AUTOSAR XML (schema 4-2-2)
package /STELLANTIS/EPT/ASWCs
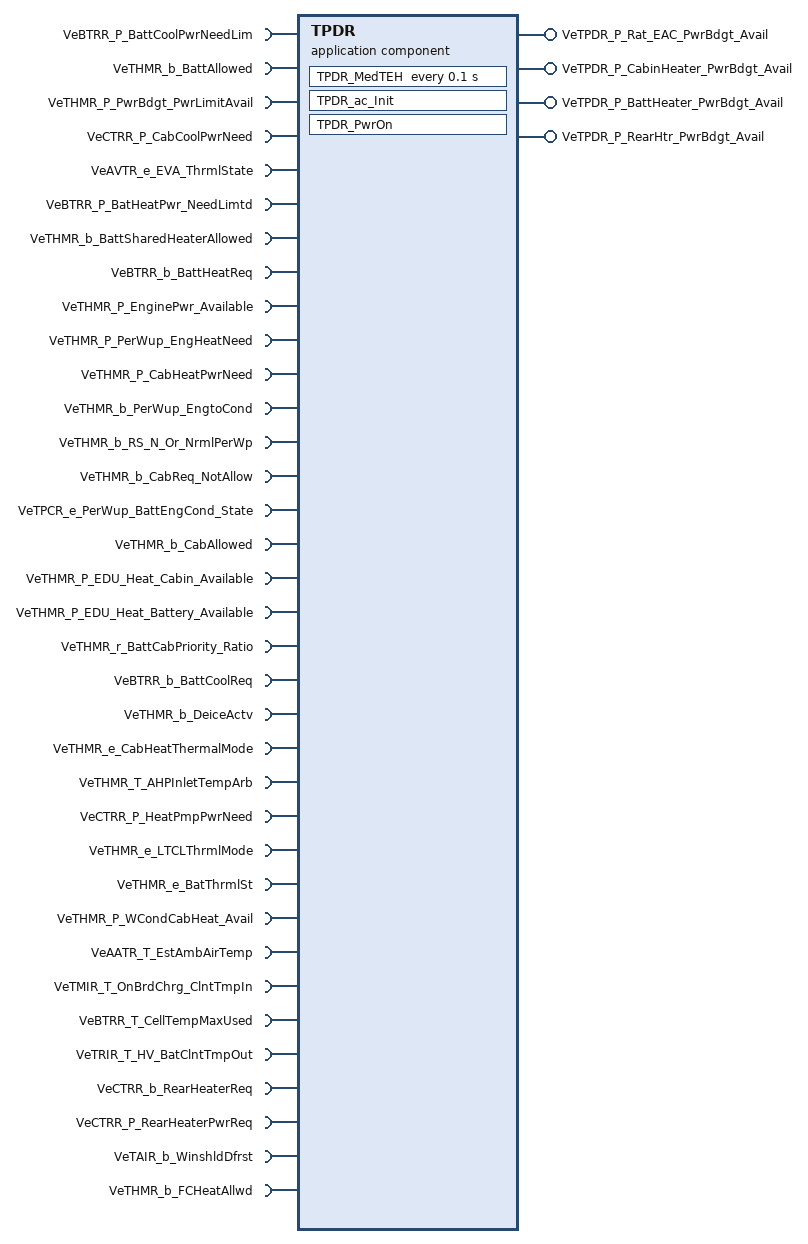
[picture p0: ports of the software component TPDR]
  application sw component type TPDR
    35 x require port:
      VeBTRR_P_BattCoolPwrNeedLim: nonqueued-receiver-com-spec{data-element=Value, init-value=0}, required-interface=VeBTRR_P_BattCoolPwrNeedLim
      VeTHMR_b_BattAllowed: nonqueued-receiver-com-spec{data-element=Value, init-value=0}, required-interface=VeTHMR_b_BattAllowed
      VeTHMR_P_PwrBdgt_PwrLimitAvail: nonqueued-receiver-com-spec{data-element=Value, init-value=0}, required-interface=VeTHMR_P_PwrBdgt_PwrLimitAvail
      VeCTRR_P_CabCoolPwrNeed: nonqueued-receiver-com-spec{data-element=Value, init-value=0}, required-interface=VeCTRR_P_CabCoolPwrNeed
      VeAVTR_e_EVA_ThrmlState: nonqueued-receiver-com-spec{data-element=Value, init-value=CeAVTR_e_NoEVACond}, required-interface=VeAVTR_e_EVA_ThrmlState
      VeBTRR_P_BatHeatPwr_NeedLimtd: nonqueued-receiver-com-spec{data-element=Value, init-value=0}, required-interface=VeBTRR_P_BatHeatPwr_NeedLimtd
      VeTHMR_b_BattSharedHeaterAllowed: nonqueued-receiver-com-spec{data-element=Value, init-value=0}, required-interface=VeTHMR_b_BattSharedHeaterAllowed
      VeBTRR_b_BattHeatReq: nonqueued-receiver-com-spec{data-element=Value, init-value=0}, required-interface=VeBTRR_b_BattHeatReq
      VeTHMR_P_EnginePwr_Available: nonqueued-receiver-com-spec{data-element=Value, init-value=0}, required-interface=VeTHMR_P_EnginePwr_Available
      VeTHMR_P_PerWup_EngHeatNeed: nonqueued-receiver-com-spec{data-element=Value, init-value=0}, required-interface=VeTHMR_P_PerWup_EngHeatNeed
      VeTHMR_P_CabHeatPwrNeed: nonqueued-receiver-com-spec{data-element=Value, init-value=0}, required-interface=VeTHMR_P_CabHeatPwrNeed
      VeTHMR_b_PerWup_EngtoCond: nonqueued-receiver-com-spec{data-element=Value, init-value=0}, required-interface=VeTHMR_b_PerWup_EngtoCond
      VeTHMR_b_RS_N_Or_NrmlPerWp: nonqueued-receiver-com-spec{data-element=Value, init-value=0}, required-interface=VeTHMR_b_RS_N_Or_NrmlPerWp
      VeTHMR_b_CabReq_NotAllow: nonqueued-receiver-com-spec{data-element=Value, init-value=0}, required-interface=VeTHMR_b_CabReq_NotAllow
      VeTPCR_e_PerWup_BattEngCond_State: nonqueued-receiver-com-spec{data-element=Value, init-value=CeTPCR_e_NoneOfEngBatt_Cond}, required-interface=VeTPCR_e_PerWup_BattEngCond_State
      VeTHMR_b_CabAllowed: nonqueued-receiver-com-spec{data-element=Value, init-value=0}, required-interface=VeTHMR_b_CabAllowed
      VeTHMR_P_EDU_Heat_Cabin_Available: nonqueued-receiver-com-spec{data-element=Value, init-value=0}, required-interface=VeTHMR_P_EDU_Heat_Cabin_Available
      VeTHMR_P_EDU_Heat_Battery_Available: nonqueued-receiver-com-spec{data-element=Value, init-value=0}, required-interface=VeTHMR_P_EDU_Heat_Battery_Available
      VeTHMR_r_BattCabPriority_Ratio: nonqueued-receiver-com-spec{data-element=Value, init-value=0}, required-interface=VeTHMR_r_BattCabPriority_Ratio
      VeBTRR_b_BattCoolReq: nonqueued-receiver-com-spec{data-element=Value, init-value=0}, required-interface=VeBTRR_b_BattCoolReq
      VeTHMR_b_DeiceActv: nonqueued-receiver-com-spec{data-element=Value, init-value=0}, required-interface=VeTHMR_b_DeiceActv
      VeTHMR_e_CabHeatThermalMode: nonqueued-receiver-com-spec{data-element=Value, init-value=CeTHMR_e_NoActvHeat}, required-interface=VeTHMR_e_CabHeatThermalMode
      VeTHMR_T_AHPInletTempArb: nonqueued-receiver-com-spec{data-element=Value, init-value=0}, required-interface=VeTHMR_T_AHPInletTempArb
      VeCTRR_P_HeatPmpPwrNeed: nonqueued-receiver-com-spec{data-element=Value, init-value=0}, required-interface=VeCTRR_P_HeatPmpPwrNeed
      VeTHMR_e_LTCLThrmlMode: nonqueued-receiver-com-spec{data-element=Value, init-value=CeTHMR_e_LTCLBalancing}, required-interface=VeTHMR_e_LTCLThrmlMode
      VeTHMR_e_BatThrmlSt: nonqueued-receiver-com-spec{data-element=Value, init-value=CeTHMR_e_NoConditioning}, required-interface=VeTHMR_e_BatThrmlSt
      VeTHMR_P_WCondCabHeat_Avail: nonqueued-receiver-com-spec{data-element=Value, init-value=0}, required-interface=VeTHMR_P_WCondCabHeat_Avail
      VeAATR_T_EstAmbAirTemp: nonqueued-receiver-com-spec{data-element=Value, init-value=0}, required-interface=VeAATR_T_EstAmbAirTemp
      VeTMIR_T_OnBrdChrg_ClntTmpIn: nonqueued-receiver-com-spec{data-element=Value, init-value=0}, required-interface=VeTMIR_T_OnBrdChrg_ClntTmpIn
      VeBTRR_T_CellTempMaxUsed: nonqueued-receiver-com-spec{data-element=Value, init-value=0}, required-interface=VeBTRR_T_CellTempMaxUsed
      VeTRIR_T_HV_BatClntTmpOut: nonqueued-receiver-com-spec{data-element=Value, init-value=0}, required-interface=VeTRIR_T_HV_BatClntTmpOut
      VeCTRR_b_RearHeaterReq: nonqueued-receiver-com-spec{data-element=Value, init-value=0}, required-interface=VeCTRR_b_RearHeaterReq
      VeCTRR_P_RearHeaterPwrReq: nonqueued-receiver-com-spec{data-element=Value, init-value=0}, required-interface=VeCTRR_P_RearHeaterPwrReq
      VeTAIR_b_WinshldDfrst: nonqueued-receiver-com-spec{data-element=Value, init-value=0}, required-interface=VeTAIR_b_WinshldDfrst
      VeTHMR_b_FCHeatAllwd: nonqueued-receiver-com-spec{data-element=Value, init-value=0}, required-interface=VeTHMR_b_FCHeatAllwd
    4 x provide port, all with nonqueued-sender-com-spec{data-element=Value, init-value=0}:
      VeTPDR_P_Rat_EAC_PwrBdgt_Avail: provided-interface=VeTPDR_P_Rat_EAC_PwrBdgt_Avail
      VeTPDR_P_CabinHeater_PwrBdgt_Avail: provided-interface=VeTPDR_P_CabinHeater_PwrBdgt_Avail
      VeTPDR_P_BattHeater_PwrBdgt_Avail: provided-interface=VeTPDR_P_BattHeater_PwrBdgt_Avail
      VeTPDR_P_RearHtr_PwrBdgt_Avail: provided-interface=VeTPDR_P_RearHtr_PwrBdgt_Avail
    behavior IB_TPDR: data-type-mapping=msADTtoIDTMapping, handle-termination-and-restart=NO-SUPPORT
      timing event Event_MedTEH: start-on-event=TPDR_MedTEH, period=0.1
      init event Event_TPDR_ac_Init: start-on-event=TPDR_ac_Init
      init event Event_PwrOn: start-on-event=TPDR_PwrOn
      runnable TPDR_ac_Init
        data-send-points:
          4 x access:
            OUT_VeTPDR_P_Rat_EAC_PwrBdgt_Avail_Value: accessed-variable=VeTPDR_P_Rat_EAC_PwrBdgt_Avail.Value
            OUT_VeTPDR_P_CabinHeater_PwrBdgt_Avail_Value: accessed-variable=VeTPDR_P_CabinHeater_PwrBdgt_Avail.Value
            OUT_VeTPDR_P_BattHeater_PwrBdgt_Avail_Value: accessed-variable=VeTPDR_P_BattHeater_PwrBdgt_Avail.Value
            OUT_VeTPDR_P_RearHtr_PwrBdgt_Avail_Value: accessed-variable=VeTPDR_P_RearHtr_PwrBdgt_Avail.Value
      runnable TPDR_MedTEH
        data-receive-point-by-arguments:
          35 x access:
            IN_VeAATR_T_EstAmbAirTemp_Value: accessed-variable=VeAATR_T_EstAmbAirTemp.Value
            IN_VeAVTR_e_EVA_ThrmlState_Value: accessed-variable=VeAVTR_e_EVA_ThrmlState.Value
            IN_VeBTRR_P_BatHeatPwr_NeedLimtd_Value: accessed-variable=VeBTRR_P_BatHeatPwr_NeedLimtd.Value
            IN_VeBTRR_P_BattCoolPwrNeedLim_Value: accessed-variable=VeBTRR_P_BattCoolPwrNeedLim.Value
            IN_VeBTRR_T_CellTempMaxUsed_Value: accessed-variable=VeBTRR_T_CellTempMaxUsed.Value
            IN_VeBTRR_b_BattCoolReq_Value: accessed-variable=VeBTRR_b_BattCoolReq.Value
            IN_VeBTRR_b_BattHeatReq_Value: accessed-variable=VeBTRR_b_BattHeatReq.Value
            IN_VeCTRR_P_CabCoolPwrNeed_Value: accessed-variable=VeCTRR_P_CabCoolPwrNeed.Value
            IN_VeCTRR_P_HeatPmpPwrNeed_Value: accessed-variable=VeCTRR_P_HeatPmpPwrNeed.Value
            IN_VeCTRR_P_RearHeaterPwrReq_Value: accessed-variable=VeCTRR_P_RearHeaterPwrReq.Value
            IN_VeCTRR_b_RearHeaterReq_Value: accessed-variable=VeCTRR_b_RearHeaterReq.Value
            IN_VeTAIR_b_WinshldDfrst_Value: accessed-variable=VeTAIR_b_WinshldDfrst.Value
            IN_VeTHMR_P_CabHeatPwrNeed_Value: accessed-variable=VeTHMR_P_CabHeatPwrNeed.Value
            IN_VeTHMR_P_EDU_Heat_Battery_Available_Value: accessed-variable=VeTHMR_P_EDU_Heat_Battery_Available.Value
            IN_VeTHMR_P_EDU_Heat_Cabin_Available_Value: accessed-variable=VeTHMR_P_EDU_Heat_Cabin_Available.Value
            IN_VeTHMR_P_EnginePwr_Available_Value: accessed-variable=VeTHMR_P_EnginePwr_Available.Value
            IN_VeTHMR_P_PerWup_EngHeatNeed_Value: accessed-variable=VeTHMR_P_PerWup_EngHeatNeed.Value
            IN_VeTHMR_P_PwrBdgt_PwrLimitAvail_Value: accessed-variable=VeTHMR_P_PwrBdgt_PwrLimitAvail.Value
            IN_VeTHMR_P_WCondCabHeat_Avail_Value: accessed-variable=VeTHMR_P_WCondCabHeat_Avail.Value
            IN_VeTHMR_T_AHPInletTempArb_Value: accessed-variable=VeTHMR_T_AHPInletTempArb.Value
            IN_VeTHMR_b_BattAllowed_Value: accessed-variable=VeTHMR_b_BattAllowed.Value
            IN_VeTHMR_b_BattSharedHeaterAllowed_Value: accessed-variable=VeTHMR_b_BattSharedHeaterAllowed.Value
            IN_VeTHMR_b_CabAllowed_Value: accessed-variable=VeTHMR_b_CabAllowed.Value
            IN_VeTHMR_b_CabReq_NotAllow_Value: accessed-variable=VeTHMR_b_CabReq_NotAllow.Value
            IN_VeTHMR_b_DeiceActv_Value: accessed-variable=VeTHMR_b_DeiceActv.Value
            IN_VeTHMR_b_FCHeatAllwd_Value: accessed-variable=VeTHMR_b_FCHeatAllwd.Value
            IN_VeTHMR_b_PerWup_EngtoCond_Value: accessed-variable=VeTHMR_b_PerWup_EngtoCond.Value
            IN_VeTHMR_b_RS_N_Or_NrmlPerWp_Value: accessed-variable=VeTHMR_b_RS_N_Or_NrmlPerWp.Value
            IN_VeTHMR_e_BatThrmlSt_Value: accessed-variable=VeTHMR_e_BatThrmlSt.Value
            IN_VeTHMR_e_CabHeatThermalMode_Value: accessed-variable=VeTHMR_e_CabHeatThermalMode.Value
            IN_VeTHMR_e_LTCLThrmlMode_Value: accessed-variable=VeTHMR_e_LTCLThrmlMode.Value
            IN_VeTHMR_r_BattCabPriority_Ratio_Value: accessed-variable=VeTHMR_r_BattCabPriority_Ratio.Value
            IN_VeTMIR_T_OnBrdChrg_ClntTmpIn_Value: accessed-variable=VeTMIR_T_OnBrdChrg_ClntTmpIn.Value
            IN_VeTPCR_e_PerWup_BattEngCond_State_Value: accessed-variable=VeTPCR_e_PerWup_BattEngCond_State.Value
            IN_VeTRIR_T_HV_BatClntTmpOut_Value: accessed-variable=VeTRIR_T_HV_BatClntTmpOut.Value
        data-send-points:
          4 x access:
            OUT_VeTPDR_P_CabinHeater_PwrBdgt_Avail_Value: accessed-variable=VeTPDR_P_CabinHeater_PwrBdgt_Avail.Value
            OUT_VeTPDR_P_BattHeater_PwrBdgt_Avail_Value: accessed-variable=VeTPDR_P_BattHeater_PwrBdgt_Avail.Value
            OUT_VeTPDR_P_Rat_EAC_PwrBdgt_Avail_Value: accessed-variable=VeTPDR_P_Rat_EAC_PwrBdgt_Avail.Value
            OUT_VeTPDR_P_RearHtr_PwrBdgt_Avail_Value: accessed-variable=VeTPDR_P_RearHtr_PwrBdgt_Avail.Value
      runnable TPDR_PwrOn
        data-send-points:
          4 x access:
            OUT_VeTPDR_P_Rat_EAC_PwrBdgt_Avail_Value: accessed-variable=VeTPDR_P_Rat_EAC_PwrBdgt_Avail.Value
            OUT_VeTPDR_P_CabinHeater_PwrBdgt_Avail_Value: accessed-variable=VeTPDR_P_CabinHeater_PwrBdgt_Avail.Value
            OUT_VeTPDR_P_BattHeater_PwrBdgt_Avail_Value: accessed-variable=VeTPDR_P_BattHeater_PwrBdgt_Avail.Value
            OUT_VeTPDR_P_RearHtr_PwrBdgt_Avail_Value: accessed-variable=VeTPDR_P_RearHtr_PwrBdgt_Avail.Value
      variation point proxy Variant_TPDR_1: category=CONDITION, condition-access=1
